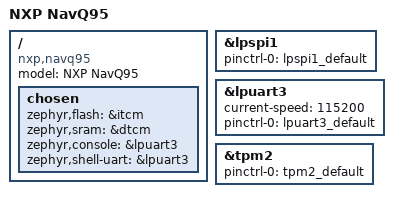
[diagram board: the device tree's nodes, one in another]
/*
 * Copyright 2024 NXP
 *
 * SPDX-License-Identifier: Apache-2.0
 */

/dts-v1/;

#include <nxp/nxp_imx95_m7.dtsi>
#include "navq95-pinctrl.dtsi"

/ {
	model = "NXP NavQ95";
	compatible = "nxp,navq95";

	chosen {
		/* TCM */
		zephyr,flash = &itcm;
		zephyr,sram = &dtcm;

		zephyr,console = &lpuart3;
		zephyr,shell-uart = &lpuart3;
	};
};

&lpspi1 {
	pinctrl-0 = <&lpspi1_default>;
	pinctrl-names = "default";
	status = "okay";
};

&lpuart3 {
	status = "okay";
	current-speed = <115200>;
	pinctrl-0 = <&lpuart3_default>;
	pinctrl-names = "default";
};

&tpm2 {
	pinctrl-0 = <&tpm2_default>;
	pinctrl-names = "default";
	status = "okay";
};
